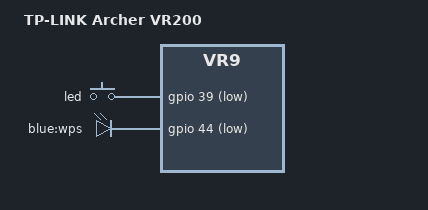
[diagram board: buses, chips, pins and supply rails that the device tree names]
#include "vr9_tplink_vr200.dtsi"

/ {
	compatible = "tplink,vr200", "lantiq,xway", "lantiq,vr9";
	model = "TP-LINK Archer VR200";

	chosen {
		bootargs = "console=ttyLTQ0,115200";
	};
};

&keys {
	led {
		label = "led";
		gpios = <&gpio 39 GPIO_ACTIVE_LOW>;
		linux,code = <KEY_LIGHTS_TOGGLE>;
	};
};

&leds {
	wps {
		label = "blue:wps";
		gpios = <&gpio 44 GPIO_ACTIVE_LOW>;
	};
};
